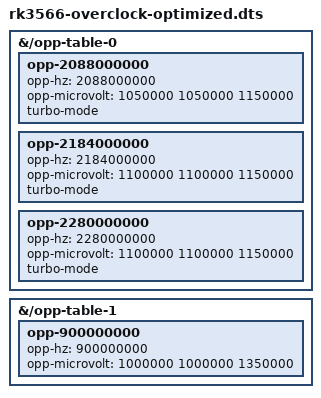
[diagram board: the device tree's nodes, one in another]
/*
 * RK3566 Optimized Overclock
 *
 * CPU: Add turbo boost OPPs at stock-safe voltages.
 *   2088 MHz @ 1050mV — ATF-validated, within stock voltage envelope
 *   2184 MHz @ 1100mV — ATF-validated, within stock voltage envelope
 *   2280 MHz @ 1100mV — same voltage as 2184, +4.4% freq at no extra cost
 *
 * GPU: Add 900 MHz OPP.
 *   Mali-G52 EE runs at 900 MHz on RK3562 in mainline DTS (same core).
 *
 * Stack with an undervolt DTBO for reduced thermals.
 */
/dts-v1/;
/plugin/;

/ {
fragment@0 {
	target-path = "/opp-table-0";
	__overlay__ {
		opp-2088000000 {
			opp-hz = /bits/ 64 <2088000000>;
			opp-microvolt = <1050000 1050000 1150000>;
			turbo-mode;
		};
		opp-2184000000 {
			opp-hz = /bits/ 64 <2184000000>;
			opp-microvolt = <1100000 1100000 1150000>;
			turbo-mode;
		};
		opp-2280000000 {
			opp-hz = /bits/ 64 <2280000000>;
			opp-microvolt = <1100000 1100000 1150000>;
			turbo-mode;
		};
	};
};
fragment@1 {
	target-path = "/opp-table-1";
	__overlay__ {
		opp-900000000 {
			opp-hz = /bits/ 64 <900000000>;
			opp-microvolt = <1000000 1000000 1350000>;
		};
	};
};
};
